# STM32WB55 register map
File version: 2.0
CPU: CM4 r0p1, little endian, MPU, FPU, 4 interrupt priority bits
Registers are 32-bit, read-write, reset 0x0 unless marked. A register's access mark holds for its fields unless they carry their own. Offsets are from the block's base; [hi:lo] are bit positions; {n}, {i} and the like mark numbered series; 'fields as' and 'values as' point back to an identical list.

## COMP — Comparator instance 1
Base 0x40010200
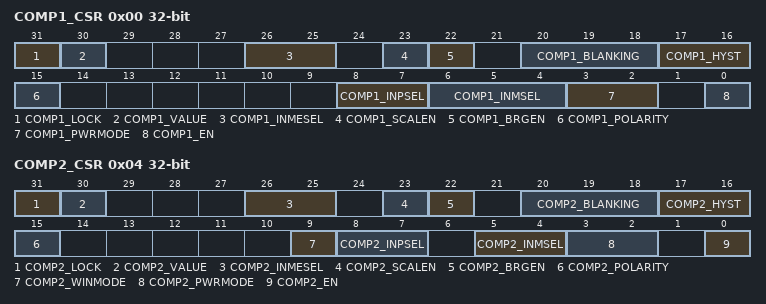
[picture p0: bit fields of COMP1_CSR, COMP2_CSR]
0x00 COMP1_CSR access per field — Comparator control and status register
  [31] COMP1_LOCK rw — Comparator lock
  [30] COMP1_VALUE ro — Comparator output level
  [26:25] COMP1_INMESEL rw — Comparator input minus extended selection
  [23] COMP1_SCALEN rw — Comparator scaler bridge enable
  [22] COMP1_BRGEN rw — Comparator voltage scaler enable
  [20:18] COMP1_BLANKING rw — Comparator blanking source
  [17:16] COMP1_HYST rw — Comparator hysteresis
  [15] COMP1_POLARITY rw — Comparator output polarity
  [8:7] COMP1_INPSEL rw — Comparator input plus selection
  [6:4] COMP1_INMSEL rw — Comparator input minus selection
  [3:2] COMP1_PWRMODE rw — Comparator power mode
  [0] COMP1_EN rw — Comparator enable
0x04 COMP2_CSR access per field — Comparator 2 control and status register
  [31] COMP2_LOCK rw — CSR register lock bit
  [30] COMP2_VALUE ro — Comparator 2 output status bit
  [26:25] COMP2_INMESEL rw — comparator 2 input minus extended selection bits.
  [23] COMP2_SCALEN rw — Voltage scaler enable bit
  [22] COMP2_BRGEN rw — Scaler bridge enable
  [20:18] COMP2_BLANKING rw — Comparator 2 blanking source selection bits
  [17:16] COMP2_HYST rw — Comparator 2 hysteresis selection bits
  [15] COMP2_POLARITY rw — Comparator 2 polarity selection bit
  [9] COMP2_WINMODE rw — Windows mode selection bit
  [8:7] COMP2_INPSEL rw — Comparator 1 input plus selection bit
  [5:4] COMP2_INMSEL rw — Comparator 2 input minus selection bits
  [3:2] COMP2_PWRMODE rw — Power Mode of the comparator 2
  [0] COMP2_EN rw — Comparator 2 enable bit

## RNG — Random number generator
Base 0x58001000
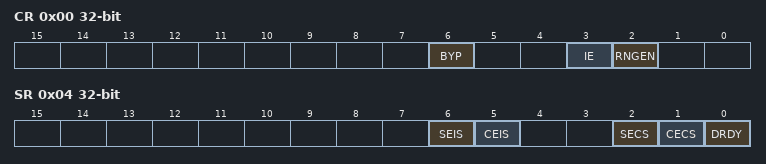
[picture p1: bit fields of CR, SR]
0x00 CR — control register
  [6] BYP — Bypass mode enable
  [3] IE — Interrupt enable
    0=Disabled (RNG interrupt is disabled); 1=Enabled (RNG interrupt is enabled)
  [2] RNGEN — Random number generator enable
    0=Disabled (Random number generator is disabled); 1=Enabled (Random number generator is enabled)
0x04 SR access per field — status register
  [6] SEIS rw write-0-clears — Seed error interrupt status
    on write: 0=Clear flag | on read: 0=No faulty sequence detected; 1=Fault (At least one faulty sequence has been detected. See **SECS** bit description for details. An interrupt is pending if IE = 1 in the RNG_CR register.)
  [5] CEIS rw write-0-clears — Clock error interrupt status
    on write: 0=Clear flag | on read: 0=Correct (The RNG clock is correct); 1=Slow (The RNG has been detected too slow An interrupt is pending if IE = 1 in the RNG_CR register)
  [2] SECS ro — Seed error current status
    0=No faulty sequence has currently been detected. If the SEIS bit is set, this means that a faulty sequence was detected and the situation has been recovered.; 1=Fault (At least one faulty sequence has been detected - see ref manual for details)
  [1] CECS ro — Clock error current status
    0=Correct (The RNG clock is correct. If the CEIS bit is set, this means that a slow clock was detected and the situation has been recovered.); 1=Slow (The RNG clock is too slow)
  [0] DRDY ro — Data ready
    0=Invalid (The RNG_DR register is not yet valid, no random data is available); 1=Valid (The RNG_DR register contains valid random data. Once the RNG_DR register has been read, this bit returns to 0 until a new random value is generated.)
0x08 DR ro — data register
  [31:0] RNDATA — Random data

## HSEM
Base 0x58001400
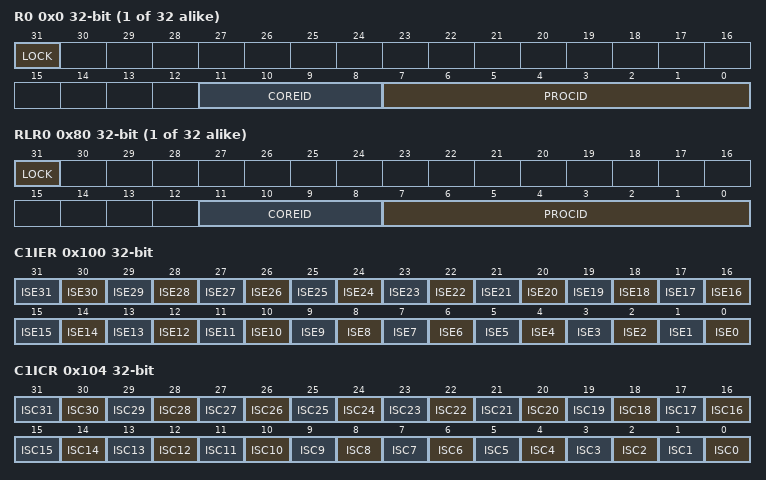
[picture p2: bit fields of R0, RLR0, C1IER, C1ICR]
{0x0+4i} R{i} (i=0..31) — HSEM register HSEM_R{i}
  [31] LOCK — lock indication
    on read: 0=Free (Semaphore is free); 1=Locked (Semaphore is locked) | on write: 0=Free semaphore; 1=TryLock (Try to lock semaphore)
  [11:8] COREID — Semaphore CoreID
  [7:0] PROCID — Semaphore ProcessID
{0x80+4i} RLR{i} (i=0..31) ro — Semaphore {i} read lock register
  [31] LOCK — lock indication
    0=Free (Semaphore is free); 1=Locked (Semaphore is locked)
  [11:8] COREID — Semaphore CoreID
  [7:0] PROCID — Semaphore ProcessID
0x100 C1IER — HSEM Interrupt enable register
  [n] ISE{n} (n=0..31) — Interrupt semaphore {n} enable bit
    0=Disabled (Interrupt generation disabled); 1=Enabled (Interrupt generation enabled)
0x104 C1ICR — HSEM Interrupt clear register
  [n] ISC{n} (n=0..31) — Interrupt semaphore {n} clear bit
    on read: 0=NoEffect (Always reads 0) | on write: 0=NoEffect (Interrupt semaphore x status ISFx and masked status MISFx not affected); 1=Clear (Interrupt semaphore x status ISFx and masked status MISFx cleared)
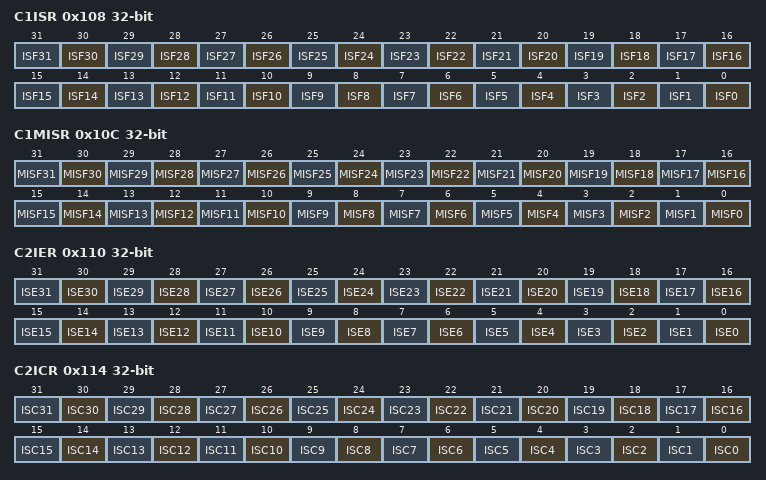
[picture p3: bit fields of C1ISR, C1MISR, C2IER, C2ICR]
0x108 C1ISR ro — HSEM Interrupt status register
  [n] ISF{n} (n=0..31) — Interrupt semaphore {n} status bit before enable (mask)
    0=NotPending (No interrupt pending); 1=Pending (Interrupt pending)
0x10C C1MISR ro — HSEM Masked interrupt status register
  [n] MISF{n} (n=0..31) — Masked interrupt semaphore {n} status bit after enable (mask)
    0=NotPending (No interrupt pending after masking); 1=Pending (Interrupt pending after masking)
0x110 C2IER — HSEM Interrupt enable register
  fields as C1IER
0x114 C2ICR — HSEM Interrupt clear register
  fields as C1ICR
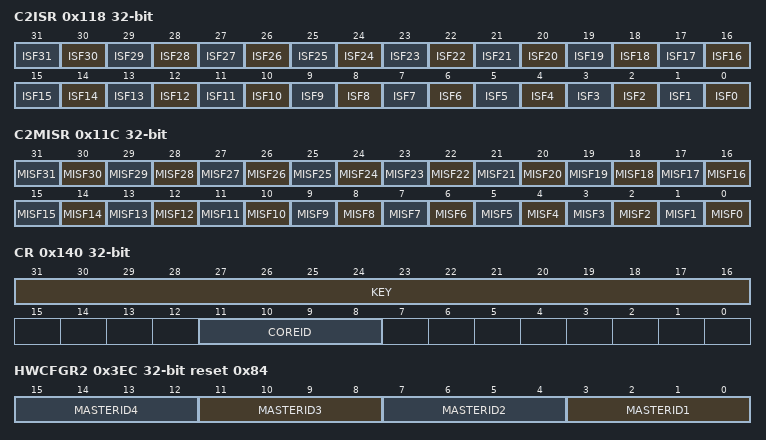
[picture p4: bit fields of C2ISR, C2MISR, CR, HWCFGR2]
0x118 C2ISR ro — HSEM Interrupt status register
  fields as C1ISR
0x11C C2MISR ro — HSEM Masked interrupt status register
  fields as C1MISR
0x140 CR — Semaphore Clear register
  [31:16] KEY — Semaphore clear Key
  [11:8] COREID — CoreID of semaphore to be cleared
0x144 KEYR — Interrupt clear register
  [31:16] KEY — Semaphore Clear Key
0x3EC HWCFGR2 ro reset 0x84 — Semaphore hardware configuration register 2
  [4n-1:4n-4] MASTERID{n} (n=1..4) — Hardware Configuration valid bus masters ID{n}
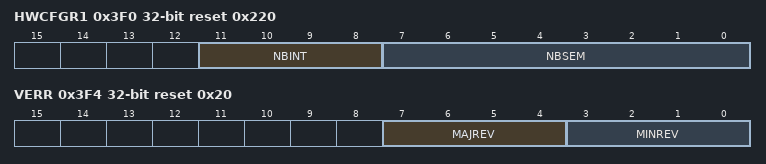
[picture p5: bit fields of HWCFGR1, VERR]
0x3F0 HWCFGR1 ro reset 0x220 — Semaphore hardware configuration register 1
  [11:8] NBINT — Hardware Configuration number of interrupts supported number of master IDs
  [7:0] NBSEM — Hardware Configuration number of semaphores
0x3F4 VERR ro reset 0x20 — HSEM version register
  [7:4] MAJREV — Major Revision
  [3:0] MINREV — Minor Revision
0x3F8 IPIDR ro reset 0x100072 — HSEM indentification register
  [31:0] ID — Identification Code
0x3FC SIDR ro reset 0xA3C5DD01 — HSEM size indentification register
  [31:0] SID — Size Identification Code
